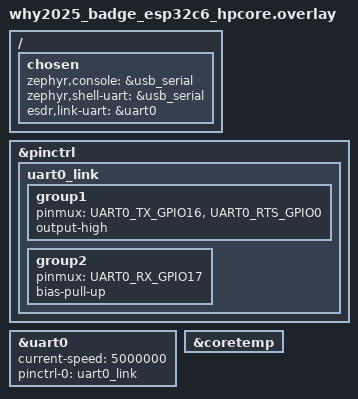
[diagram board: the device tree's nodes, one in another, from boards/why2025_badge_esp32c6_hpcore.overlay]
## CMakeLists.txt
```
# SPDX-License-Identifier: GPL-3.0-or-later

cmake_minimum_required(VERSION 3.20.0)

find_package(Zephyr REQUIRED HINTS $ENV{ZEPHYR_BASE})
project(esp_sdr_osmosdr_serial)

# The protocol header is the osmosdr app's; the crystal calibration requests (ESDR_REQ_GET_CAL,
# ESDR_REQ_SET_CAL) are the shared ones. No settings store here: the WHY2025 badge's C6 has no
# RAM for one beside its gapless ring, its P4 keeps the record (apps/micropython's ltecal).
target_include_directories(app PRIVATE ../osmosdr/src ../../include)
include(${CMAKE_CURRENT_LIST_DIR}/../common/esdr_cal.cmake)
target_sources(app PRIVATE src/main.c)
target_sources_ifdef(CONFIG_APP_LINK_SDIO app PRIVATE src/link_sdio.c)
target_sources_ifdef(CONFIG_APP_FW_UPDATE app PRIVATE src/fw_update.c)
```

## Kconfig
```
# SPDX-License-Identifier: GPL-3.0-or-later

mainmenu "ESP-SDR osmosdr over a serial link"

config APP_FREQ_MHZ
	int "Centre frequency in MHz at boot"
	range 100 6000
	default 2437

config APP_RX_DIAG
	bool "Receive through the modem diagnostic bus (ESP32-C5)"
	depends on SOC_SERIES_ESP32C5
	select ESP_SDR_DIAG
	help
	  Gapless 40 MS/s ring through the GPIO matrix and PARLIO (esp_sdr_diag.h), a boxcar
	  of 16 and a CIC in the library down to the requested rate, instead of the IQ
	  estimator polled by the CPU. Drives 8 pads as outputs while receiving; the nibble
	  window is picked from the signal level when a stream starts.

config APP_LINK_SDIO
	bool "The link is the SDIO slave (ESP32-C6)"
	depends on SOC_SERIES_ESP32C6
	help
	  The host (the WHY2025 badge's ESP32-P4) reaches the radio over SDIO function 1, 4-bit
	  (src/link_sdio.c), instead of a UART or USB-Serial-JTAG. It carries receive rates up
	  to 2 MS/s, 8-bit items above 250 kS/s.

# Where the Wi-Fi driver brings the radio up (prj.conf): no power save, and no IP traffic, the
# network stack only carries the driver, minimal. Defaults rather than prj.conf lines, which
# would warn in an image without them (the gapless one).
choice ESP32_WIFI_STA_POWER_SAVE_MODE
	default ESP32_WIFI_STA_POWER_SAVE_NONE
endchoice

configdefault NET_IPV6
	default n

configdefault NET_IPV4
	default y

configdefault NET_PKT_RX_COUNT
	default 4

configdefault NET_PKT_TX_COUNT
	default 4

configdefault NET_BUF_RX_COUNT
	default 8

configdefault NET_BUF_TX_COUNT
	default 8

configdefault NET_RX_STACK_SIZE
	default 1024

# Block 3 holds the staging ring and the stream's blocks (40 KiB with the bounce buffers).
configdefault ESP_SDR_GAPLESS_STAGE_KB
	default 64

config APP_LINK_FRAMED
	bool "Framed link on the UART, beside the plain one"
	depends on !APP_LINK_SDIO
	select UART_USE_RUNTIME_CONFIGURE
	help
	  Understand the framed serial link (esp_sdr/esdr_link.h) as well: a host that says hello gets
	  frames, with checksums and flow control and blocks of the length they have, at the
	  highest rate the UART takes; any other host goes on with esdr_proto.h's transport.

config APP_LINK_FAST
	bool
	default y
	depends on APP_LINK_FRAMED && ESDR_FPGA
	help
	  A host that asks gets the framed link's blocks through the MCH2022 badge's FPGA, over SPI
	  by DMA, if the image's bitstream (CONFIG_ESDR_FPGA_IMAGE) is the link variant.

config APP_FW_UPDATE
	bool "Firmware update over the link"
	default y if ESP_IDF_BOOTLOADER
	depends on ESP_IDF_BOOTLOADER
	select FLASH
	select CRC
	select REBOOT
	help
	  ESDR_REQ_FW_BEGIN, _WRITE and _END: the host writes a new image to the OTA
	  partition the ESP-IDF bootloader does not run, which then selects it
	  (src/fw_update.c). The way the ESP32-P4-Function-EV-Board's ESP32-C6 gets
	  updates once its esp-hosted-mcu firmware installed this app.

source "Kconfig.zephyr"
```

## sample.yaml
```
sample:
  name: ESP-SDR osmosdr over a serial link
  description: >-
    The osmosdr protocol over a serial link (USB-Serial-JTAG, a UART, SDIO):
    continuous CPU-paced receive and transmit on the ESP32-C6, for the SoapySDR
    plugin's serial backend or a P4 host
common:
  tags: esp-sdr
  platform_allow:
    - xiao_esp32c6/esp32c6/hpcore
    - why2025_badge/esp32c6/hpcore
    - esp32p4_function_ev_board/esp32c6/hpcore
    - waveshare_esp32c5_zero/esp32c5/hpcore
    - mch2022/esp32/procpu
  integration_platforms:
    - xiao_esp32c6/esp32c6/hpcore
    - waveshare_esp32c5_zero/esp32c5/hpcore
tests:
  # Needs a host: run tools/esdr_serial.py (see README). The WHY2025 badge's C6 builds the
  # gapless receiver on SDIO (its board configuration).
  sample.esp_sdr.osmosdr_serial:
    build_only: true
  # The WHY2025 badge's fallback link (uart.conf): UART0 to the P4 at 5 Mbaud instead of SDIO,
  # the image as before the gapless receiver, which needs SDIO. Twister adds the common
  # platforms to platform_allow, hence the filter.
  sample.esp_sdr.osmosdr_serial.uart_link:
    platform_allow:
      - why2025_badge/esp32c6/hpcore
    filter: CONFIG_BOARD_WHY2025_BADGE
    integration_platforms:
      - why2025_badge/esp32c6/hpcore
    extra_args:
      - EXTRA_CONF_FILE=uart.conf
    build_only: true
  # Receive from the C5's diagnostic-bus ring instead of the CPU-paced IQ estimator
  # (diag.conf); exercised by tests/regression/stream_gapless.
  sample.esp_sdr.osmosdr_serial.diag:
    platform_allow:
      - waveshare_esp32c5_zero/esp32c5/hpcore
    integration_platforms:
      - waveshare_esp32c5_zero/esp32c5/hpcore
    extra_args:
      - EXTRA_CONF_FILE=diag.conf
    build_only: true
```

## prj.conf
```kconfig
# The Wi-Fi driver brings the radio up at boot; nothing may scan or connect.
CONFIG_NETWORKING=y
CONFIG_WIFI=y
# The driver's and the IP stack's options (no power save, minimal, no IP traffic) are defaults
# in the app's Kconfig: lines here would warn in the gapless image, which has neither.

CONFIG_ESP_SDR=y
CONFIG_ESP_SDR_RX_DECIM=n

# USB-Serial-JTAG carries the protocol; the console goes to UART0 (boards/). No logging: the
# C5's RAM below its capture bank is tight.
CONFIG_LOG=n
CONFIG_MAIN_STACK_SIZE=1536
```

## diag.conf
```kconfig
# Extra configuration for the diagnostic-bus receive (ESP32-C5): -DEXTRA_CONF_FILE=diag.conf
CONFIG_APP_RX_DIAG=y
# The ring's consumer runs on the main thread.
CONFIG_MAIN_STACK_SIZE=2560
```

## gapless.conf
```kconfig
# SPDX-License-Identifier: GPL-3.0-or-later
#
# ESDR_MODE_GAPLESS for an ESP32-C6 on SDIO (CONFIG_APP_LINK_SDIO): the whole 80 MS/s without
# a gap, pruned to what the link carries (esp_sdr_gapless.h). The WHY2025 badge's C6 has these
# lines in its board configuration. The ring takes SRAM blocks 1 and 2, so the image must fit
# block 0: the radio comes up without the Wi-Fi driver.
CONFIG_WIFI=n
CONFIG_NETWORKING=n
CONFIG_ESP_SDR_PHY_ONLY=y
CONFIG_ESP_SDR_GAPLESS=y
# The PHY comes up (and calibrates, printing through its own printf) in main(), not in the
# Wi-Fi driver's thread: 1536 bytes overflowed.
CONFIG_MAIN_STACK_SIZE=4096
```

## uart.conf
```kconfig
# SPDX-License-Identifier: GPL-3.0-or-later
#
# The WHY2025 badge's C6 on its UART link (-DEXTRA_CONF_FILE=uart.conf): UART0 to the P4 at
# 5 Mbaud (the overlay's esdr,link-uart, up to 250 kS/s) instead of SDIO, and the image as it
# was before the gapless receiver, which needs SDIO: the Wi-Fi driver brings the radio up
# (prj.conf). Undoes the board configuration's SDIO and gapless lines.
CONFIG_APP_LINK_SDIO=n
CONFIG_ESP_SDR_GAPLESS=n
CONFIG_ESP_SDR_PHY_ONLY=n
CONFIG_WIFI=y
CONFIG_NETWORKING=y
CONFIG_MAIN_STACK_SIZE=1536
```

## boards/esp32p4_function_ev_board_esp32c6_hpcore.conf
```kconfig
# SPDX-License-Identifier: GPL-3.0-or-later
#
# The ESP32-P4-Function-EV-Board's ESP32-C6: its ESP32-P4 reaches the radio over SDIO (up to
# 2 MS/s). The console is UART0 on the ESP-Prog connector.
CONFIG_APP_LINK_SDIO=y

# ESDR_MODE_GAPLESS, as on the WHY2025 badge (gapless.conf): the whole 80 MS/s without a gap,
# pruned to what the link carries (esp_sdr_gapless.h). The ring takes SRAM blocks 1 and 2, so
# the image must fit block 0: the radio comes up without the Wi-Fi driver.
CONFIG_WIFI=n
CONFIG_NETWORKING=n
CONFIG_ESP_SDR_PHY_ONLY=y
CONFIG_ESP_SDR_GAPLESS=y
# The PHY comes up (and calibrates, printing through its own printf) in main(), not in the
# Wi-Fi driver's thread: 1536 bytes overflowed.
CONFIG_MAIN_STACK_SIZE=4096
```

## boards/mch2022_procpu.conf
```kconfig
# SPDX-License-Identifier: GPL-3.0-or-later
#
# The MCH2022 badge's ESP32: the protocol on UART0, which the badge's RP2040 bridges to its
# first USB serial port (the overlay's esdr,link-uart); no console. Receive only, in decimated
# bursts (no paced receiver on the ESP32).
CONFIG_CONSOLE=n
CONFIG_UART_CONSOLE=n
CONFIG_ESP_SDR_RX_DECIM=y
# With apps/mch2022_coproc on the RP2040, its interface 6: up to 5 Mbaud, blocks by their length.
CONFIG_APP_LINK_FRAMED=y
# The capture bank is SRAM1, where .noinit would spill otherwise.
CONFIG_ESP32_REGION_1_NOINIT=n
# The RP2040 driver clears the download reset lock, so esptool can always reach the ESP32.
CONFIG_I2C=y
CONFIG_MFD=y
```

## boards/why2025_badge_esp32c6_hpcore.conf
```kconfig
# SPDX-License-Identifier: GPL-3.0-or-later
#
# The ESP32-P4 reaches the radio over SDIO (up to 2 MS/s); built with uart.conf, over UART0 at
# 5 Mbaud (the overlay's esdr,link-uart, up to 250 kS/s), the fallback link.
CONFIG_APP_LINK_SDIO=y

# ESDR_MODE_GAPLESS (as gapless.conf): the whole 80 MS/s without a gap, pruned to what the
# link carries (esp_sdr_gapless.h). The ring takes SRAM blocks 1 and 2, so the image must fit
# block 0: the radio comes up without the Wi-Fi driver.
CONFIG_WIFI=n
CONFIG_NETWORKING=n
CONFIG_ESP_SDR_PHY_ONLY=y
CONFIG_ESP_SDR_GAPLESS=y
# The PHY comes up (and calibrates, printing through its own printf) in main(), not in the
# Wi-Fi driver's thread: 1536 bytes overflowed.
CONFIG_MAIN_STACK_SIZE=4096

# The die temperature (ESDR_REQ_GET_TEMP, the overlay enables the sensor).
CONFIG_SENSOR=y
```

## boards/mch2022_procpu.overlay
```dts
/*
 * SPDX-License-Identifier: GPL-3.0-or-later
 *
 * MCH2022 badge: the protocol on UART0 at 2 Mbaud, which the RP2040 bridges to its first USB
 * serial port; the host sets the same rate on the port (the SoapySDR module's baud=2000000).
 * No console: the ROM's boot messages come at 115200 baud and the host skips them.
 */

/ {
	chosen {
		/delete-property/ zephyr,console;
		/delete-property/ zephyr,shell-uart;
		esdr,link-uart = &uart0;
	};
};

&uart0 {
	current-speed = <2000000>;
};

/*
 * The FPGA, for the framed link's blocks when its image has the link bitstream
 * (CONFIG_ESDR_FPGA_IMAGE, gateware/esdr_fpga/link.py). The panel stays where the board has it.
 */
#include "../../../dts/esdr/mch2022_gateware.dtsi"
```

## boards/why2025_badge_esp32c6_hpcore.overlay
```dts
/*
 * SPDX-License-Identifier: GPL-3.0-or-later
 *
 * The WHY2025 badge's ESP32-C6 as the radio of its ESP32-P4: the protocol runs on UART0 (the
 * line to the P4's UART1) at 5 Mbaud, an exact divisor of the 40 MHz crystal on both chips.
 * RTS goes out on GPIO0, the line to the P4's GPIO14, which the P4 reads as CTS: it pauses
 * while the transmit ring is full. The console stays on USB-Serial-JTAG (USB-C port J8, while
 * the P4 hands the port to the C6).
 */

#include <zephyr/dt-bindings/pinctrl/esp32c6-pinctrl.h>

/ {
	chosen {
		zephyr,console = &usb_serial;
		zephyr,shell-uart = &usb_serial;
		esdr,link-uart = &uart0;
	};
};

&pinctrl {
	uart0_link: uart0_link {
		group1 {
			pinmux = <UART0_TX_GPIO16>, <UART0_RTS_GPIO0>;
			output-high;
		};

		group2 {
			pinmux = <UART0_RX_GPIO17>;
			bias-pull-up;
		};
	};
};

&uart0 {
	current-speed = <5000000>;
	pinctrl-0 = <&uart0_link>;
};

/* The die temperature for ESDR_REQ_GET_TEMP. */
&coretemp {
	status = "okay";
};
```

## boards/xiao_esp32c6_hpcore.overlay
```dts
/*
 * SPDX-License-Identifier: GPL-3.0-or-later
 *
 * The app drives USB-Serial-JTAG's FIFOs itself: Zephyr's driver stays off,
 * the console moves to UART0 (D6 TX, D7 RX).
 */

/ {
	chosen {
		zephyr,console = &uart0;
		zephyr,shell-uart = &uart0;
	};
};

&usb_serial {
	status = "disabled";
};

/* The die temperature for ESDR_REQ_GET_TEMP. */
&coretemp {
	status = "okay";
};
```

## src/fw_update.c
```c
/*
 * SPDX-License-Identifier: GPL-3.0-or-later
 *
 * Firmware update over the link, for a C6 that the ESP-IDF bootloader starts from an OTA
 * partition (CONFIG_ESP_IDF_BOOTLOADER, as the esp-hosted-mcu firmware left the EV board's C6):
 * the new image goes to the OTA partition the C6 does not run from, then the next otadata
 * entry selects it. The partitions come from the partition table, so either esp-hosted-mcu
 * layout works. The bootloader checks the image (checksum and SHA-256) at the restart and
 * stays with the running partition if it is broken.
 */

#include <errno.h>
#include <string.h>

#include <zephyr/device.h>
#include <zephyr/devicetree.h>
#include <zephyr/drivers/flash.h>
#include <zephyr/kernel.h>
#include <zephyr/sys/byteorder.h>
#include <zephyr/sys/crc.h>
#include <zephyr/sys/reboot.h>
#include <zephyr/sys/util.h>

#include "fw_update.h"

#define PART_TABLE_ADDR 0x8000U
#define PART_TABLE_ENTRIES 95U
#define PART_MAGIC 0x50aaU
#define PART_TYPE_APP 0x00U
#define PART_TYPE_DATA 0x01U
#define PART_SUBTYPE_OTA_0 0x10U
#define PART_SUBTYPE_OTA_MAX 0x1fU
#define PART_SUBTYPE_DATA_OTA 0x00U

#define SECTOR 0x1000U
#define IMAGE_MAGIC 0xe9U

/* The ESP-IDF partition table entry and otadata entry (esp_flash_partitions.h). */
struct part_entry {
	uint16_t magic;
	uint8_t type;
	uint8_t subtype;
	uint32_t offset;
	uint32_t size;
	char label[16];
	uint32_t flags;
} __packed;

struct ota_entry {
	uint32_t seq;
	uint8_t label[20];
	uint32_t state;
	uint32_t crc;
} __packed;

static const struct device *const flash = DEVICE_DT_GET(DT_PARENT(DT_CHOSEN(zephyr_flash)));

static struct {
	uint32_t ota_addr[2], ota_size[2];
	uint32_t otadata_addr;
	unsigned int ota_count;
	/* The update in progress: target partition, image size, bytes written, erased up to. */
	bool active;
	unsigned int target;
	uint32_t size, written, erased;
} fw;

/* What the ESP-IDF bootloader computes: esp_rom_crc32_le(UINT32_MAX, &seq, 4). */
static uint32_t ota_crc(uint32_t seq)
{
	uint8_t le[4];

	sys_put_le32(seq, le);
	return crc32_ieee_update(0xffffffffU, le, sizeof(le));
}

static bool ota_valid(const struct ota_entry *e)
{
	return e->seq != 0xffffffffU && e->crc == ota_crc(e->seq);
}

static int read_partitions(void)
{
	struct part_entry e;

	fw.ota_count = 0;
	fw.otadata_addr = 0;
	for (unsigned int i = 0; i < PART_TABLE_ENTRIES; i++) {
		int ret = flash_read(flash, PART_TABLE_ADDR + i * sizeof(e), &e, sizeof(e));

		if (ret != 0) {
			return ret;
		}
		if (sys_le16_to_cpu(e.magic) != PART_MAGIC) {
			break;
		}
		if (e.type == PART_TYPE_APP && e.subtype >= PART_SUBTYPE_OTA_0 &&
		    e.subtype <= PART_SUBTYPE_OTA_MAX && e.subtype - PART_SUBTYPE_OTA_0 < 2) {
			fw.ota_addr[e.subtype - PART_SUBTYPE_OTA_0] = sys_le32_to_cpu(e.offset);
			fw.ota_size[e.subtype - PART_SUBTYPE_OTA_0] = sys_le32_to_cpu(e.size);
			fw.ota_count++;
		} else if (e.type == PART_TYPE_DATA && e.subtype == PART_SUBTYPE_DATA_OTA) {
			fw.otadata_addr = sys_le32_to_cpu(e.offset);
		}
	}
	return fw.ota_count == 2U && fw.otadata_addr != 0U ? 0 : -ENOENT;
}

/* The newest valid otadata entry in either sector: its index, and its sequence number (0: none). */
static int read_otadata(unsigned int *newest_sector, uint32_t *newest_seq)
{
	*newest_sector = 0;
	*newest_seq = 0;
	for (unsigned int s = 0; s < 2U; s++) {
		struct ota_entry e;
		int ret = flash_read(flash, fw.otadata_addr + s * SECTOR, &e, sizeof(e));

		if (ret != 0) {
			return ret;
		}
		if (ota_valid(&e) && e.seq > *newest_seq) {
			*newest_seq = e.seq;
			*newest_sector = s;
		}
	}
	return 0;
}

int fw_update_begin(uint32_t size)
{
	unsigned int sector;
	uint32_t seq;
	int ret;

	fw.active = false;
	if (!device_is_ready(flash)) {
		return -ENODEV;
	}
	ret = read_partitions();
	if (ret == 0) {
		ret = read_otadata(&sector, &seq);
	}
	if (ret != 0) {
		return ret;
	}
	/* The bootloader runs partition (seq - 1) % count, the first one without an entry. */
	fw.target = seq == 0U ? 1U : (seq % fw.ota_count);
	if (size == 0U || size > fw.ota_size[fw.target]) {
		return -EFBIG;
	}
	fw.size = size;
	fw.written = 0;
	fw.erased = 0;
	fw.active = true;
	return 0;
}

int fw_update_write(uint32_t offset, const uint8_t *data, size_t len)
{
	uint32_t base = fw.ota_addr[fw.target];
	int ret;

	if (!fw.active) {
		return -EBADF;
	}
	if (offset != fw.written || len == 0U || len % 4U != 0U || fw.size - offset < len) {
		return -EINVAL;
	}
	if (offset == 0U && data[0] != IMAGE_MAGIC) {
		return -EINVAL;
	}
	/* Erase as the image grows, a sector at a time: each request stays short. */
	while (fw.erased < offset + len) {
		ret = flash_erase(flash, base + fw.erased, SECTOR);
		if (ret != 0) {
			return ret;
		}
		fw.erased += SECTOR;
	}
	ret = flash_write(flash, base + offset, data, len);
	if (ret != 0) {
		return ret;
	}
	fw.written += len;
	return 0;
}

static void reboot_work_fn(struct k_work *work)
{
	ARG_UNUSED(work);
	sys_reboot(SYS_REBOOT_COLD);
}

static K_WORK_DELAYABLE_DEFINE(reboot_work, reboot_work_fn);

int fw_update_end(uint32_t crc)
{
	uint8_t buf[256];
	uint32_t got = 0;
	unsigned int sector;
	uint32_t seq;
	struct ota_entry e;
	int ret;

	if (!fw.active || fw.written != fw.size) {
		return -EBADF;
	}
	fw.active = false;
	for (uint32_t off = 0; off < fw.size; off += sizeof(buf)) {
		size_t n = MIN(sizeof(buf), fw.size - off);

		ret = flash_read(flash, fw.ota_addr[fw.target] + off, buf, n);
		if (ret != 0) {
			return ret;
		}
		got = crc32_ieee_update(got, buf, n);
	}
	if (got != crc) {
		return -EIO;
	}

	/* The next sequence number that selects the target, in the older sector. */
	ret = read_otadata(&sector, &seq);
	if (ret != 0) {
		return ret;
	}
	do {
		seq++;
	} while ((seq - 1U) % fw.ota_count != fw.target);
	memset(&e, 0xff, sizeof(e));
	e.seq = seq;
	e.crc = ota_crc(seq);
	sector = seq == 1U ? 0U : 1U - sector;
	ret = flash_erase(flash, fw.otadata_addr + sector * SECTOR, SECTOR);
	if (ret == 0) {
		ret = flash_write(flash, fw.otadata_addr + sector * SECTOR, &e, sizeof(e));
	}
	if (ret != 0) {
		return ret;
	}
	/* Restart once the reply is out. */
	k_work_schedule(&reboot_work, K_MSEC(200));
	return 0;
}
```

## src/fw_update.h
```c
/*
 * SPDX-License-Identifier: GPL-3.0-or-later
 *
 * Firmware update over the link (fw_update.c): ESDR_REQ_FW_BEGIN, _WRITE and _END.
 */

#ifndef FW_UPDATE_H_
#define FW_UPDATE_H_

#include <stddef.h>
#include <stdint.h>

/* Start an image of size bytes for the OTA partition the C6 does not run from. */
int fw_update_begin(uint32_t size);
/* The next len bytes (a multiple of 4) at offset, in order. */
int fw_update_write(uint32_t offset, const uint8_t *data, size_t len);
/* Check the image against crc (CRC-32/IEEE), select it and restart into it. */
int fw_update_end(uint32_t crc);

#endif /* FW_UPDATE_H_ */
```

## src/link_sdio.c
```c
/*
 * SPDX-License-Identifier: GPL-3.0-or-later
 *
 * The ESP32-C6 SDIO slave driven through the HAL's LL layer (there is no Zephyr driver):
 * function 1, 4-bit, the host's SLC protocol as esp-hosted uses it.
 *
 * - Host to slave: RX_BUFS buffers of RX_BUF_BYTES, each loaded one raises the token count the
 *   host reads before it writes. Writes land in them in order; the app reads them as a byte
 *   stream and hands each emptied buffer back.
 * - Slave to host: a queue of descriptors over the caller's buffers. While the DMA is idle,
 *   everything queued goes out as one chain and the byte counter (PKT_LEN) the host polls
 *   rises by its length; once the host has read the chain (EOF), its buffers are retired.
 *
 * - A host that (re)starts raises general-purpose interrupt 0 (it writes bit 0 of its
 *   register 0x08C): the send queue is dropped (its blocks count as done), the byte counter
 *   and the tokens start again, so that a host enumerating anew finds no chain of the last
 *   session in the way.
 *
 * Nothing here takes interrupts: the paced and gapless receivers run with them locked and pump
 * between samples, so what they call lives in IRAM (a flash cache miss would stall them).
 */

#include <string.h>

#include <zephyr/kernel.h>
#include <zephyr/sys/util.h>

#include <esp_attr.h>
#include <hal/gpio_ll.h>
#include <hal/sdio_slave_ll.h>
#include <soc/gpio_struct.h>

#include "link_sdio.h"

/* Slot 0's IOMUX pins (function 0). */
#define PIN_CMD 18
#define PIN_CLK 19
#define PIN_D0  20
#define PIN_D1  21
#define PIN_D2  22
#define PIN_D3  23

#define RX_BUFS      16U
#define RX_BUF_BYTES 512U
/* Send queue entries, a power of 2; at most CHAIN_MAX in one chain, so that the rest stay the
 * app's to fill while the host reads it. */
#define SQ 32U
#define CHAIN_MAX 4U

static slc_dev_t *slc;

static sdio_slave_ll_desc_t rx_desc[RX_BUFS] __aligned(4);
static uint8_t rx_buf[RX_BUFS][RX_BUF_BYTES] __aligned(4);
static uint32_t rx_cur, rx_off, rx_tail;

static struct {
	sdio_slave_ll_desc_t desc[SQ];
	bool block[SQ];
	/* Running counters: queued up to head, the chain in flight is [start, end). */
	uint32_t head, start, end;
	uint32_t pkt_len, blocks_done;
} tx __aligned(4);

static void pin(int gpio, bool pullup)
{
	gpio_ll_pulldown_dis(&GPIO, gpio);
	gpio_ll_input_enable(&GPIO, gpio);
	gpio_ll_func_sel(&GPIO, gpio, 0);
	gpio_ll_set_drive_capability(&GPIO, gpio, GPIO_DRIVE_CAP_3);
	if (pullup) {
		gpio_ll_pullup_en(&GPIO, gpio);
	} else {
		gpio_ll_pullup_dis(&GPIO, gpio);
	}
}

void sdio_link_init(void)
{
	hinf_dev_t *hinf = sdio_slave_ll_get_hinf(0);
	host_dev_t *host = sdio_slave_ll_get_host(0);

	slc = sdio_slave_ll_get_slc(0);
	pin(PIN_CLK, false);
	pin(PIN_CMD, true);
	pin(PIN_D0, true);
	pin(PIN_D1, true);
	pin(PIN_D2, true);
	pin(PIN_D3, true);

	sdio_slave_ll_enable_bus_clock(true);
	sdio_slave_ll_reset_register();
	sdio_slave_ll_init(slc);
	sdio_slave_ll_init_version(hinf);
	sdio_slave_ll_enable_hs(hinf, true);
	sdio_slave_ll_set_timing(host, SDIO_SLAVE_TIMING_PSEND_PSAMPLE);

	/* Send: the done check reads the masked status (enabled, not routed to the CPU). */
	sdio_slave_ll_send_write_len(slc, 0);
	sdio_slave_ll_send_intr_ena(slc, true);
	/* The host's restart (general-purpose interrupt 0), polled likewise. */
	sdio_slave_ll_slvint_t ena = SDIO_SLAVE_LL_SLVINT_0;

	sdio_slave_ll_slvint_set_ena(slc, &ena);

	/* Receive: all buffers loaded, one token each. */
	for (uint32_t k = 0; k < RX_BUFS; k++) {
		rx_desc[k] = (sdio_slave_ll_desc_t){
			.size = RX_BUF_BYTES,
			.buf = rx_buf[k],
			.owner = 1,
		};
		rx_desc[k].qe.stqe_next = k + 1U < RX_BUFS ? &rx_desc[k + 1U] : NULL;
	}
	rx_cur = 0;
	rx_off = 0;
	rx_tail = RX_BUFS - 1U;
	sdio_slave_ll_recv_reset(slc);
	sdio_slave_ll_recv_size_reset(slc);
	sdio_slave_ll_recv_start(slc, &rx_desc[0]);
	for (uint32_t k = 0; k < RX_BUFS; k++) {
		sdio_slave_ll_recv_size_inc(slc);
	}

	sdio_slave_ll_set_ioready(hinf, true);
}

/* An emptied receive buffer back to the tail of the DMA's list, with its token. */
static IRAM_ATTR void rx_recycle(uint32_t k)
{
	sdio_slave_ll_desc_t *d = &rx_desc[k];

	d->eof = 0;
	d->length = 0;
	d->qe.stqe_next = NULL;
	d->owner = 1;
	rx_desc[rx_tail].qe.stqe_next = d;
	rx_tail = k;
	sdio_slave_ll_recv_restart(slc);
	sdio_slave_ll_recv_size_inc(slc);
}

/* The host restarted: drop what it will not read, start the counters again. */
static IRAM_ATTR void host_restart(void)
{
	sdio_slave_ll_send_stop(slc);
	sdio_slave_ll_send_reset(slc);
	sdio_slave_ll_send_intr_clr(slc);
	for (uint32_t k = tx.start; k != tx.head; k++) {
		if (tx.block[k % SQ]) {
			tx.blocks_done++;
		}
	}
	tx.start = tx.end = tx.head;
	tx.pkt_len = 0;
	sdio_slave_ll_send_write_len(slc, 0);
	/* Tokens: one per buffer the DMA holds (the rest come back as the app empties them). */
	sdio_slave_ll_recv_size_reset(slc);
	for (uint32_t k = 0; k < RX_BUFS; k++) {
		if (rx_desc[k].owner != 0U) {
			sdio_slave_ll_recv_size_inc(slc);
		}
	}
}

IRAM_ATTR bool sdio_link_readable(void)
{
	sdio_slave_ll_slvint_t slv;

	sdio_slave_ll_slvint_fetch_clear(slc, &slv);
	if ((slv & SDIO_SLAVE_LL_SLVINT_0) != 0U) {
		host_restart();
	}
	for (;;) {
		const sdio_slave_ll_desc_t *d = &rx_desc[rx_cur];

		if (d->owner != 0U) {
			return false;
		}
		if (rx_off < d->length) {
			return true;
		}
		rx_recycle(rx_cur);
		rx_cur = (rx_cur + 1U) % RX_BUFS;
		rx_off = 0;
	}
}

IRAM_ATTR uint8_t sdio_link_getc(void)
{
	return rx_buf[rx_cur][rx_off++];
}

IRAM_ATTR bool sdio_link_queue(const uint8_t *p, size_t n, bool block)
{
	sdio_slave_ll_desc_t *d;

	if (tx.head - tx.start >= SQ || n == 0U || n > 16380U) {
		return false;
	}
	d = &tx.desc[tx.head % SQ];
	*d = (sdio_slave_ll_desc_t){
		.size = (n + 3U) & ~3U,
		.length = n,
		.buf = p,
	};
	tx.block[tx.head % SQ] = block;
	tx.head++;
	return true;
}

IRAM_ATTR void sdio_link_pump(void)
{
	if (tx.end != tx.start) {
		if (!sdio_slave_ll_send_done(slc)) {
			return;
		}
		for (uint32_t k = tx.start; k != tx.end; k++) {
			if (tx.block[k % SQ]) {
				tx.blocks_done++;
			}
		}
		tx.start = tx.end;
	}
	if (tx.head == tx.end) {
		return;
	}
	/* What is queued, CHAIN_MAX at most, as one chain; the host's counter rises by its length. */
	uint32_t bytes = 0;
	uint32_t stop = tx.head - tx.end > CHAIN_MAX ? tx.end + CHAIN_MAX : tx.head;

	for (uint32_t k = tx.end; k != stop; k++) {
		sdio_slave_ll_desc_t *d = &tx.desc[k % SQ];
		bool last = k + 1U == stop;

		d->eof = last;
		d->owner = 1;
		d->qe.stqe_next = last ? NULL : &tx.desc[(k + 1U) % SQ];
		bytes += d->length;
	}
	sdio_slave_ll_send_stop(slc);
	sdio_slave_ll_send_reset(slc);
	sdio_slave_ll_send_intr_clr(slc);
	sdio_slave_ll_send_start(slc, &tx.desc[tx.end % SQ]);
	tx.pkt_len += bytes;
	sdio_slave_ll_send_write_len(slc, tx.pkt_len);
	tx.end = stop;
}

IRAM_ATTR uint32_t sdio_link_pending(void)
{
	return tx.head - tx.start;
}

IRAM_ATTR uint32_t sdio_link_blocks_done(void)
{
	return tx.blocks_done;
}
```

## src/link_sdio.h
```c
/*
 * SPDX-License-Identifier: GPL-3.0-or-later
 *
 * The SDIO slave of the ESP32-C6 as the link to the host (link_sdio.c): the same byte stream
 * as on a UART (esdr_proto.h, serial transport), the host's writes in, the replies and
 * receive blocks out by DMA from the caller's buffers.
 */

#ifndef LINK_SDIO_H_
#define LINK_SDIO_H_

#include <stdbool.h>
#include <stddef.h>
#include <stdint.h>

/* Pins, clock and DMA; the host may enumerate once it returns. */
void sdio_link_init(void);

/* A byte the host wrote is waiting; the next one. */
bool sdio_link_readable(void);
uint8_t sdio_link_getc(void);

/*
 * Queue @p n bytes at @p p (4-byte aligned, at most 16380) to send; @p block counts it in
 * sdio_link_blocks_done(). The buffer stays the DMA's until it is done. False when the queue
 * is full.
 */
bool sdio_link_queue(const uint8_t *p, size_t n, bool block);

/* Retire what the host has read and offer it what is queued. Cheap: call between samples. */
void sdio_link_pump(void);

/* Buffers queued and not yet read by the host. */
uint32_t sdio_link_pending(void);

/* Blocks (sdio_link_queue(..., true)) the host has read, a running count. */
uint32_t sdio_link_blocks_done(void);

#endif /* LINK_SDIO_H_ */
```
